# PIC32MK1024GPL064 register map
Vendor: Microchip
Registers are 32-bit, read-write, no defined reset value unless marked. A register's access mark holds for its fields unless they carry their own. Addresses are absolute, and some are shared; only a register's first bit layout is shown; [hi:lo] are bit positions; {n}, {i} and the like mark numbered series; 'fields as' and 'values as' point back to an identical list.

## PORTD
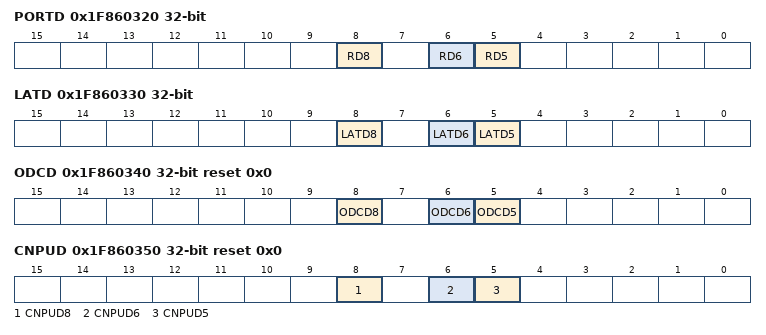
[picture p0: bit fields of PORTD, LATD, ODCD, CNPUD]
0x1F860320 PORTD — (power-on value -----------------------x-xx-----)
  [8] RD8, [6] RD6, [5] RD5
0x1F860330 LATD — (power-on value -----------------------x-xx-----)
  [8] LATD8, [6] LATD6, [5] LATD5
0x1F860340 ODCD reset 0x0
  [8] ODCD8, [6] ODCD6, [5] ODCD5
0x1F860350 CNPUD reset 0x0
  [8] CNPUD8, [6] CNPUD6, [5] CNPUD5
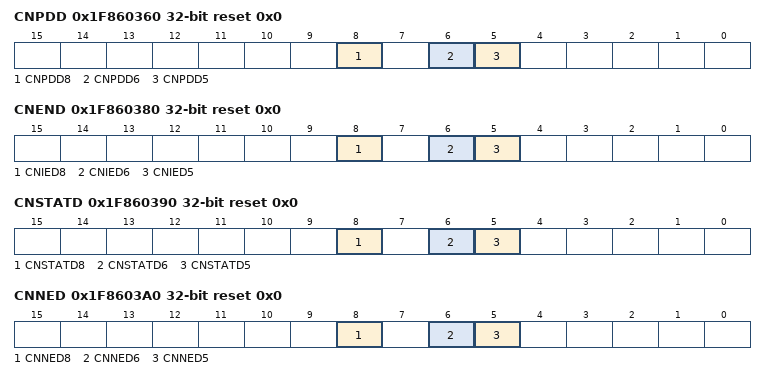
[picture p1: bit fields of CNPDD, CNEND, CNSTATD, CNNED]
0x1F860360 CNPDD reset 0x0
  [8] CNPDD8, [6] CNPDD6, [5] CNPDD5
0x1F860370 CNCOND access not given
0x1F860380 CNEND reset 0x0
  [8] CNIED8, [6] CNIED6, [5] CNIED5
0x1F860390 CNSTATD reset 0x0
  [8] CNSTATD8, [6] CNSTATD6, [5] CNSTATD5
0x1F8603A0 CNNED reset 0x0
  [8] CNNED8, [6] CNNED6, [5] CNNED5
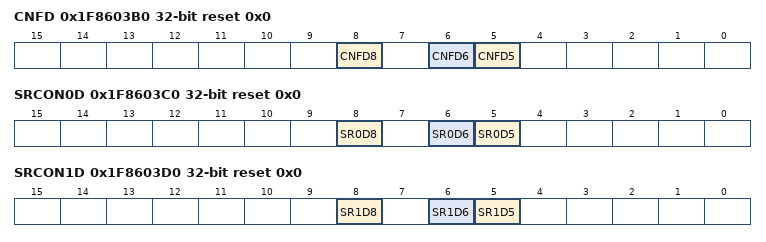
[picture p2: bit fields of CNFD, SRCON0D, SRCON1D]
0x1F8603B0 CNFD reset 0x0
  [8] CNFD8, [6] CNFD6, [5] CNFD5
0x1F8603C0 SRCON0D reset 0x0
  [8] SR0D8, [6] SR0D6, [5] SR0D5
0x1F8603D0 SRCON1D reset 0x0
  [8] SR1D8, [6] SR1D6, [5] SR1D5

## PORTE
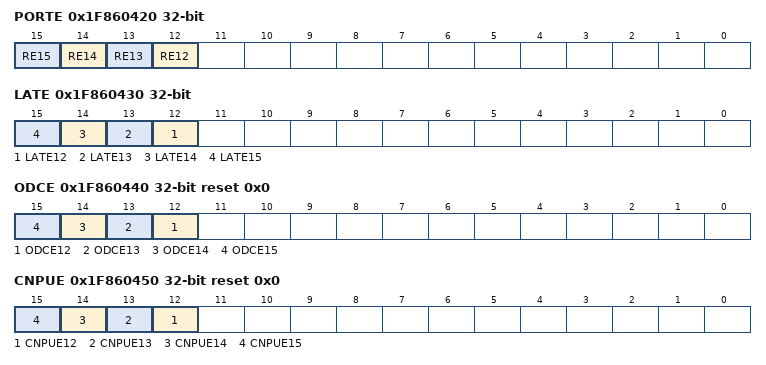
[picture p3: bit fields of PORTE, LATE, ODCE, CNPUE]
0x1F860420 PORTE — (power-on value ----------------xxxx------------)
  [n] RE{n} (n=12..15)
0x1F860430 LATE — (power-on value ----------------xxxx------------)
  [n] LATE{n} (n=12..15)
0x1F860440 ODCE reset 0x0
  [n] ODCE{n} (n=12..15)
0x1F860450 CNPUE reset 0x0
  [n] CNPUE{n} (n=12..15)
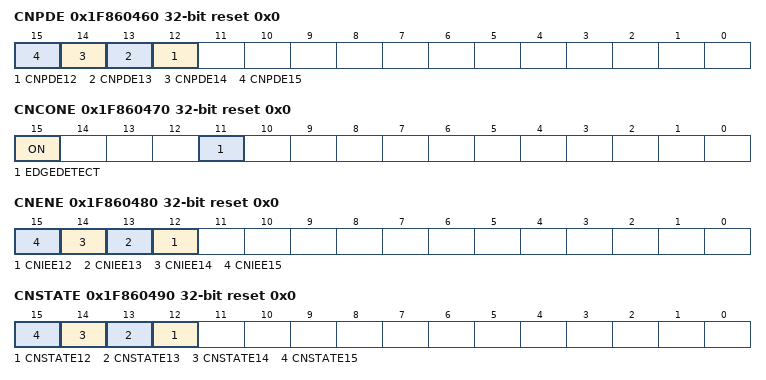
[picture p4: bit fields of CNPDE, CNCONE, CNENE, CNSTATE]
0x1F860460 CNPDE reset 0x0
  [n] CNPDE{n} (n=12..15)
0x1F860470 CNCONE reset 0x0
  [15] ON, [11] EDGEDETECT
0x1F860480 CNENE reset 0x0
  [n] CNIEE{n} (n=12..15)
0x1F860490 CNSTATE reset 0x0
  [n] CNSTATE{n} (n=12..15)
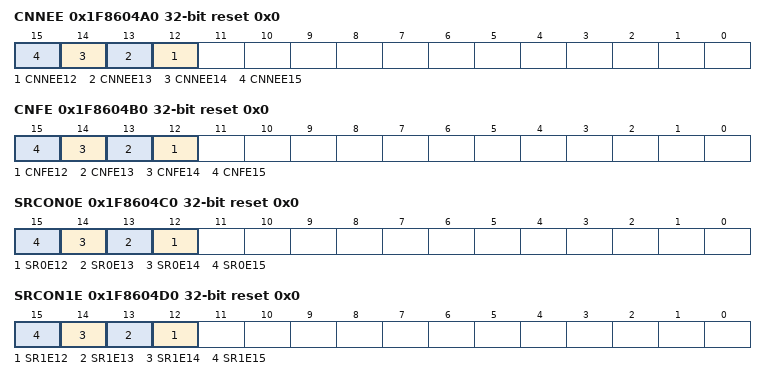
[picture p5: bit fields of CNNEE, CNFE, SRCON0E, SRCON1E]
0x1F8604A0 CNNEE reset 0x0
  [n] CNNEE{n} (n=12..15)
0x1F8604B0 CNFE reset 0x0
  [n] CNFE{n} (n=12..15)
0x1F8604C0 SRCON0E reset 0x0
  [n] SR0E{n} (n=12..15)
0x1F8604D0 SRCON1E reset 0x0
  [n] SR1E{n} (n=12..15)

## PORTF
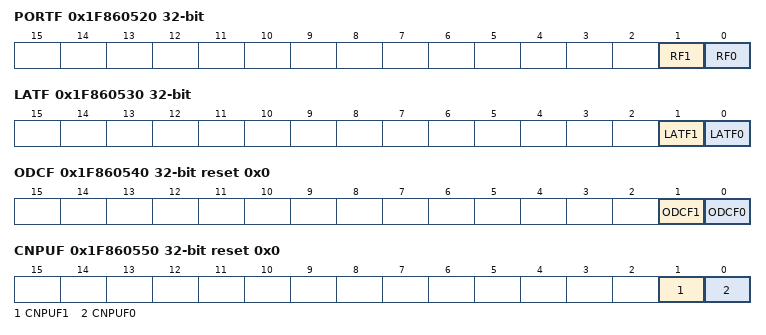
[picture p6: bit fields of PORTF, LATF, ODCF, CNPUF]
0x1F860520 PORTF — (power-on value ------------------------------xx)
  [1] RF1, [0] RF0
0x1F860530 LATF — (power-on value ------------------------------xx)
  [1] LATF1, [0] LATF0
0x1F860540 ODCF reset 0x0
  [1] ODCF1, [0] ODCF0
0x1F860550 CNPUF reset 0x0
  [1] CNPUF1, [0] CNPUF0
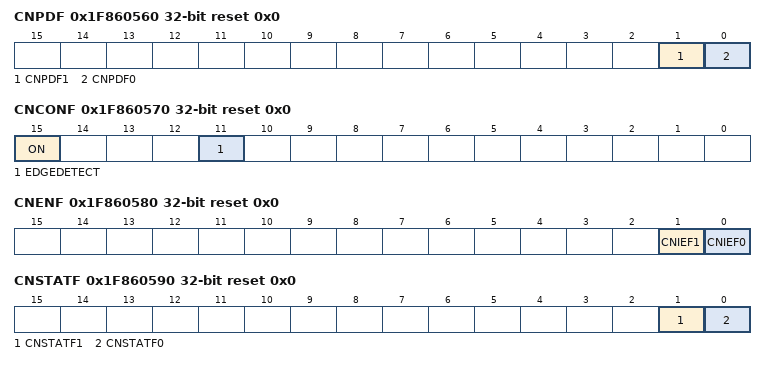
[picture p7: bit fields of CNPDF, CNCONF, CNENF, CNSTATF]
0x1F860560 CNPDF reset 0x0
  [1] CNPDF1, [0] CNPDF0
0x1F860570 CNCONF reset 0x0
  [15] ON, [11] EDGEDETECT
0x1F860580 CNENF reset 0x0
  [1] CNIEF1, [0] CNIEF0
0x1F860590 CNSTATF reset 0x0
  [1] CNSTATF1, [0] CNSTATF0
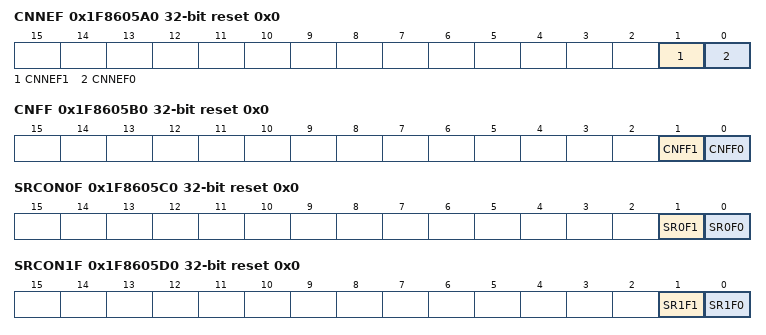
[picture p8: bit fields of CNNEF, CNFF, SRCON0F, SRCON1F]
0x1F8605A0 CNNEF reset 0x0
  [1] CNNEF1, [0] CNNEF0
0x1F8605B0 CNFF reset 0x0
  [1] CNFF1, [0] CNFF0
0x1F8605C0 SRCON0F reset 0x0
  [1] SR0F1, [0] SR0F0
0x1F8605D0 SRCON1F reset 0x0
  [1] SR1F1, [0] SR1F0

## PORTG
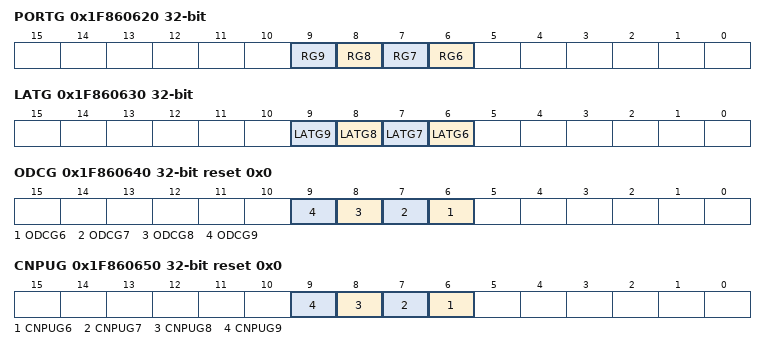
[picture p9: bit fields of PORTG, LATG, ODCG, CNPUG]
0x1F860620 PORTG — (power-on value ----------------------xxxx------)
  [n] RG{n} (n=6..9)
0x1F860630 LATG — (power-on value ----------------------xxxx------)
  [n] LATG{n} (n=6..9)
0x1F860640 ODCG reset 0x0
  [n] ODCG{n} (n=6..9)
0x1F860650 CNPUG reset 0x0
  [n] CNPUG{n} (n=6..9)
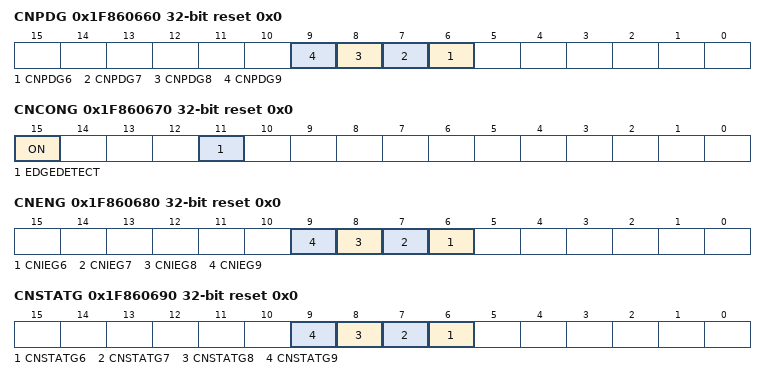
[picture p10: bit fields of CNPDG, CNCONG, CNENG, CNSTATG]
0x1F860660 CNPDG reset 0x0
  [n] CNPDG{n} (n=6..9)
0x1F860670 CNCONG reset 0x0
  [15] ON, [11] EDGEDETECT
0x1F860680 CNENG reset 0x0
  [n] CNIEG{n} (n=6..9)
0x1F860690 CNSTATG reset 0x0
  [n] CNSTATG{n} (n=6..9)
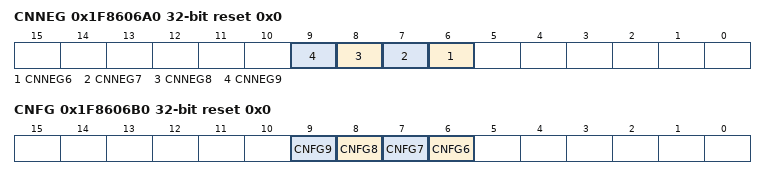
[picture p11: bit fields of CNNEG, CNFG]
0x1F8606A0 CNNEG reset 0x0
  [n] CNNEG{n} (n=6..9)
0x1F8606B0 CNFG reset 0x0
  [n] CNFG{n} (n=6..9)

## adc_sar_ctrl_upb
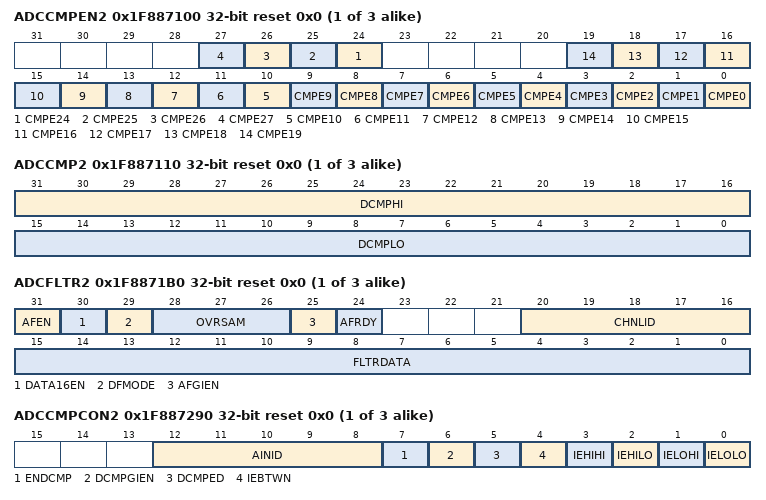
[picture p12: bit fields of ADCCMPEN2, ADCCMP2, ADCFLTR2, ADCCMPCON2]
{0x1F8870C0+0x20*i} ADCCMPEN{i} reset 0x0 (i=2..4)
  [n] CMPE{n} (n=24..27), [n] CMPE{n} (n=0..19)
{0x1F8870D0+0x20*i} ADCCMP{i} reset 0x0 (i=2..4)
  [31:16] DCMPHI, [15:0] DCMPLO
{0x1F887190+0x10*i} ADCFLTR{i} reset 0x0 (i=2..4)
  [31] AFEN, [30] DATA16EN, [29] DFMODE, [28:26] OVRSAM, [25] AFGIEN, [24] AFRDY ro, [20:16] CHNLID, [15:0] FLTRDATA ro
{0x1F887270+0x10*i} ADCCMPCON{i} reset 0x0 (i=2..4)
  [12:8] AINID ro, [7] ENDCMP, [6] DCMPGIEN, [5] DCMPED ro, [4] IEBTWN, [3] IEHIHI, [2] IEHILO, [1] IELOHI, [0] IELOLO
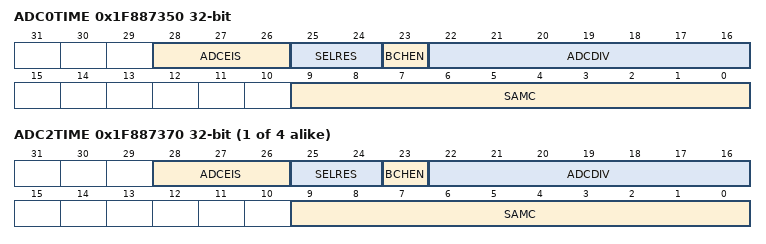
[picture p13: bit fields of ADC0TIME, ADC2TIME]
0x1F887350 ADC0TIME — (power-on value ---00000x0000000------0000000000)
  [28:26] ADCEIS, [25:24] SELRES, [23] BCHEN, [22:16] ADCDIV, [9:0] SAMC
{0x1F887350+0x10*i} ADC{i}TIME (i=2..5) — (power-on value ---00000x0000000------0000000000)
  fields as ADC0TIME
